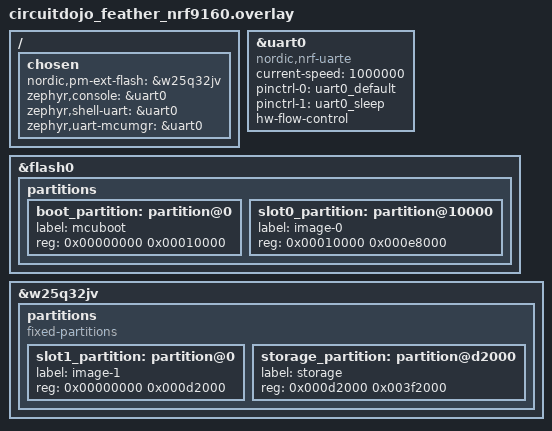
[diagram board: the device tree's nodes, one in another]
&uart0 {
  status = "okay";
  compatible = "nordic,nrf-uarte";
  current-speed = <1000000>;
  pinctrl-0 = <&uart0_default>;
  pinctrl-1 = <&uart0_sleep>;
  pinctrl-names = "default", "sleep";
  hw-flow-control;
};

/delete-node/ &boot_partition;
/delete-node/ &slot0_partition;
/delete-node/ &slot1_partition;
/delete-node/ &storage_partition;

&flash0 {
  partitions {
    boot_partition: partition@0 {
      label = "mcuboot";
      reg = <0x00000000 0x00010000>;
    };
    slot0_partition: partition@10000 {
      label = "image-0";
      reg = <0x00010000 0x000e8000>;
    };
  };
};

&w25q32jv {
  partitions {
    compatible = "fixed-partitions";
    #address-cells = <1>;
    #size-cells = <1>;
    slot1_partition: partition@0 {
      label = "image-1";
      reg = <0x00000000 0x000d2000>;
    };

    storage_partition: partition@d2000 {
      label = "storage";
      reg = <0x000d2000 0x003f2000>;
    };
  };
};

/ {
  chosen {
    nordic,pm-ext-flash = &w25q32jv;
    zephyr,console = &uart0;
    zephyr,shell-uart = &uart0;
    zephyr,uart-mcumgr = &uart0;
  };
};
